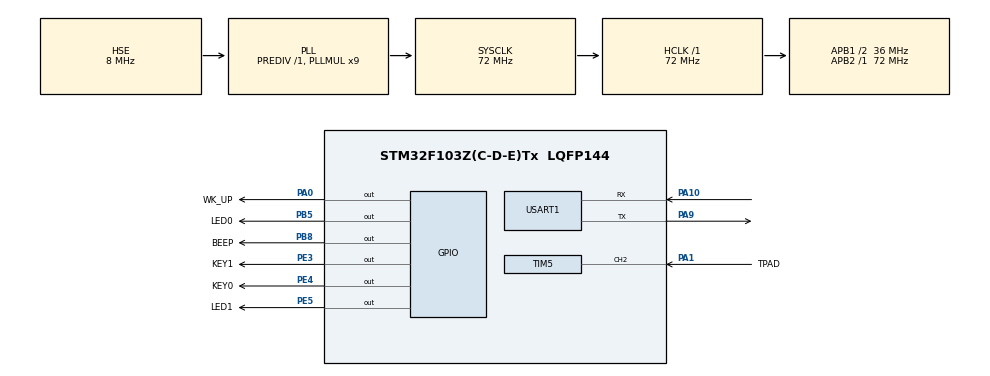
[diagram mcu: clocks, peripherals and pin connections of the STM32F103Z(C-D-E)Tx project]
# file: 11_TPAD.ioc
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Mcu.Family=STM32F1
Mcu.Name=STM32F103Z(C-D-E)Tx
Mcu.Package=LQFP144
NVIC.PriorityGroup=NVIC_PRIORITYGROUP_2
NVIC.USART1_IRQn=true\:2\:2\:true\:false\:true\:true\:true\:true
OSC_IN.Mode=HSE-External-Oscillator
OSC_IN.Signal=RCC_OSC_IN
OSC_OUT.Mode=HSE-External-Oscillator
OSC_OUT.Signal=RCC_OSC_OUT
PA0-WKUP.GPIO_Label=WK_UP
PA0-WKUP.GPIO_PuPd=GPIO_PULLDOWN
PA0-WKUP.GPIO_Speed=GPIO_SPEED_FREQ_HIGH
PA0-WKUP.PinState=GPIO_PIN_RESET
PA0-WKUP.Signal=GPIO_Output
PA1.GPIO_Label=TPAD
PA1.GPIO_PuPd=GPIO_PULLDOWN
PA1.Signal=S_TIM5_CH2
PA10.Mode=Asynchronous
PA10.Signal=USART1_RX
PA13.Mode=Serial_Wire
PA13.Signal=SYS_JTMS-SWDIO
PA14.Mode=Serial_Wire
PA14.Signal=SYS_JTCK-SWCLK
PA9.Mode=Asynchronous
PA9.Signal=USART1_TX
PB5.GPIO_Label=LED0
PB5.GPIO_PuPd=GPIO_PULLUP
PB5.GPIO_Speed=GPIO_SPEED_FREQ_HIGH
PB5.PinState=GPIO_PIN_SET
PB5.Signal=GPIO_Output
PB8.GPIO_Label=BEEP
PB8.GPIO_ModeDefaultOutputPP=GPIO_MODE_OUTPUT_PP
PB8.GPIO_PuPd=GPIO_PULLDOWN
PB8.GPIO_Speed=GPIO_SPEED_FREQ_HIGH
PB8.PinState=GPIO_PIN_RESET
PB8.Signal=GPIO_Output
PC14-OSC32_IN.Mode=LSE-External-Oscillator
PC14-OSC32_IN.Signal=RCC_OSC32_IN
PC15-OSC32_OUT.Mode=LSE-External-Oscillator
PC15-OSC32_OUT.Signal=RCC_OSC32_OUT
PE3.GPIO_Label=KEY1
PE3.GPIO_PuPd=GPIO_PULLUP
PE3.GPIO_Speed=GPIO_SPEED_FREQ_HIGH
PE3.PinState=GPIO_PIN_SET
PE3.Signal=GPIO_Output
PE4.GPIO_Label=KEY0
PE4.GPIO_PuPd=GPIO_PULLUP
PE4.GPIO_Speed=GPIO_SPEED_FREQ_HIGH
PE4.PinState=GPIO_PIN_SET
PE4.Signal=GPIO_Output
PE5.GPIO_Label=LED1
PE5.GPIO_PuPd=GPIO_PULLUP
PE5.GPIO_Speed=GPIO_SPEED_FREQ_HIGH
PE5.PinState=GPIO_PIN_SET
PE5.Signal=GPIO_Output
ProjectManager.HeapSize=0x200
ProjectManager.StackSize=0x400
ProjectManager.TargetToolchain=STM32CubeIDE
RCC.AHBFreq_Value=72000000
RCC.APB1CLKDivider=RCC_HCLK_DIV2
RCC.APB1Freq_Value=36000000
RCC.APB1TimFreq_Value=72000000
RCC.APB2Freq_Value=72000000
RCC.APB2TimFreq_Value=72000000
RCC.HCLKFreq_Value=72000000
RCC.PLLMUL=RCC_PLL_MUL9
RCC.PLLSourceVirtual=RCC_PLLSOURCE_HSE
RCC.SYSCLKFreq_VALUE=72000000
RCC.SYSCLKSource=RCC_SYSCLKSOURCE_PLLCLK
RCC.USBFreq_Value=72000000
SH.S_TIM5_CH2.0=TIM5_CH2,Input_Capture2_from_TI2
TIM5.AutoReloadPreload=TIM_AUTORELOAD_PRELOAD_ENABLE
TIM5.Channel-Input_Capture2_from_TI2=TIM_CHANNEL_2
TIM5.Prescaler=6 - 1
USART1.VirtualMode=VM_ASYNC
VP_TIM5_VS_ClockSourceINT.Mode=Internal
board=custom

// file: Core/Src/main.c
/* USER CODE BEGIN Header */

/* USER CODE END Header */
#include "main.h"
#include "tim.h"
#include "usart.h"
#include "gpio.h"

/* USER CODE BEGIN Includes */
#include "../../BSP/LED/led.h"
#include "../../BSP/KEY/key.h"
#include "../../BSP/TPAD/tpad.h"
#include "../../SYSTEM/delay/delay.h"
/* USER CODE END Includes */

void SystemClock_Config(void);

int main(void)
{
  /* USER CODE BEGIN 1 */
    uint8_t t = 0;
  /* USER CODE END 1 */

  /* MCU Configuration--------------------------------------------------------*/

  /* Reset of all peripherals, Initializes the Flash interface and the Systick. */
  HAL_Init();

  /* Configure the system clock */
  SystemClock_Config();

  /* USER CODE BEGIN SysInit */
  delay_init(72);						   	/* 初始化延时函数 */
  /* USER CODE END SysInit */

  /* Initialize all configured peripherals */
  MX_GPIO_Init();
  MX_USART1_UART_Init();
  MX_TIM5_Init();
  /* USER CODE BEGIN 2 */
  tpad_init(6);                       /* 初始化触摸按键 */
  /* USER CODE END 2 */

  /* Infinite loop */
  /* USER CODE BEGIN WHILE */
  while (1)
  {
	  if (tpad_scan(0)) /* 成功捕获到了一次上升沿(此函数执行时间至少15ms) */
	  {
		  LED1_TOGGLE(); /* LED1翻转 */
	  }

	  t++;
	  if (t == 15)
	  {
		  t = 0;
		  LED0_TOGGLE(); /* LED0翻转 */
	  }

	  delay_ms(10);
    /* USER CODE END WHILE */

  }
}

void SystemClock_Config(void)
{
  RCC_OscInitTypeDef RCC_OscInitStruct = {0};
  RCC_ClkInitTypeDef RCC_ClkInitStruct = {0};

  /** Initializes the RCC Oscillators according to the specified parameters
  * in the RCC_OscInitTypeDef structure.
  */
  RCC_OscInitStruct.OscillatorType = RCC_OSCILLATORTYPE_HSE;
  RCC_OscInitStruct.HSEState = RCC_HSE_ON;
  RCC_OscInitStruct.HSEPredivValue = RCC_HSE_PREDIV_DIV1;
  RCC_OscInitStruct.HSIState = RCC_HSI_ON;
  RCC_OscInitStruct.PLL.PLLState = RCC_PLL_ON;
  RCC_OscInitStruct.PLL.PLLSource = RCC_PLLSOURCE_HSE;
  RCC_OscInitStruct.PLL.PLLMUL = RCC_PLL_MUL9;
  if (HAL_RCC_OscConfig(&RCC_OscInitStruct) != HAL_OK)
  {
    Error_Handler();
  }

  /** Initializes the CPU, AHB and APB buses clocks
  */
  RCC_ClkInitStruct.ClockType = RCC_CLOCKTYPE_HCLK|RCC_CLOCKTYPE_SYSCLK
                              |RCC_CLOCKTYPE_PCLK1|RCC_CLOCKTYPE_PCLK2;
  RCC_ClkInitStruct.SYSCLKSource = RCC_SYSCLKSOURCE_PLLCLK;
  RCC_ClkInitStruct.AHBCLKDivider = RCC_SYSCLK_DIV1;
  RCC_ClkInitStruct.APB1CLKDivider = RCC_HCLK_DIV2;
  RCC_ClkInitStruct.APB2CLKDivider = RCC_HCLK_DIV1;

  if (HAL_RCC_ClockConfig(&RCC_ClkInitStruct, FLASH_LATENCY_2) != HAL_OK)
  {
    Error_Handler();
  }
}

void Error_Handler(void)
{
  __disable_irq();
  while (1)
  {
  }
}
